# RA6M2 register map
Vendor: Renesas Electronics Corporation; Series: RA6; File version: 1.1
CPU: CM4 r0p1, little endian, MPU, FPU, VTOR, 4 interrupt priority bits
Registers are 8-bit, read-write, reset 0x0 unless marked. A register's access mark holds for its fields unless they carry their own. Offsets are from the block's base; [hi:lo] are bit positions; 'fields as' and 'values as' point back to an identical list.

## PMISC — Miscellaneous Port Control Register
Base 0x40040D00
0x00 PFENET — Ethernet Control Register
  [4] PHYMODE0 — Ethernet Mode Setting ch0
    0=RMII mode (ETHERC channel 0); 1=MII mode (ETHERC channel 0)
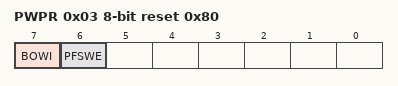
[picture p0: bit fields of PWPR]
0x03 PWPR reset 0x80 — Write-Protect Register
  [7] BOWI — PFSWE Bit Write Disable
    0=Writing to the PFSWE bit is enabled; 1=Writing to the PFSWE bit is disabled
  [6] PFSWE — PFS Register Write Enable
    0=Writing to the PFS register is disabled; 1=Writing to the PFS register is enabled

## CAC — Clock Frequency Accuracy Measurement Circuit
Base 0x40044600
0x00 CACR0 — CAC Control Register 0
  [0] CFME — Clock Frequency Measurement Enable.
    0=Disable; 1=Enable
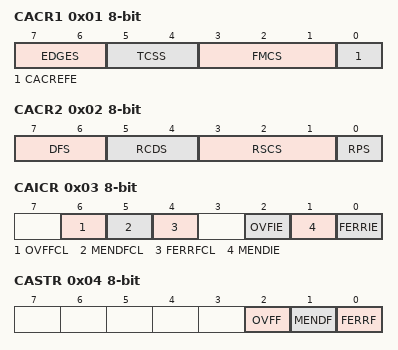
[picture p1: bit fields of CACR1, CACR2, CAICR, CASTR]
0x01 CACR1 — CAC Control Register 1
  [7:6] EDGES — Valid Edge Select
    0=Rising edge; 1=Falling edge; 2=Both rising and falling edges; 3=Setting prohibited
  [5:4] TCSS — Measurement Target Clock Frequency Division Ratio Select
    0=No division; 1=x 1/4 clock; 2=x 1/8 clock; 3=x 1/32 clock
  [3:1] FMCS — Measurement Target Clock Select
    0=Main clock; 1=Sub-clock; 2=HOCO clock; 3=MOCO clock; 4=LOCO clock; 5=Peripheral module clock(PCLKB); 6=IWDTCLK clock; 7=Setting prohibited
  [0] CACREFE — CACREF Pin Input Enable
    0=Disable; 1=Enable
0x02 CACR2 — CAC Control Register 2
  [7:6] DFS — Digital Filter Selection
    0=Digital filtering is disabled; 1=The sampling clock for the digital filter is the frequency measuring clock; 2=The sampling clock for the digital filter is the frequency measuring clock divided by 4; 3=The sampling clock for the digital filter is the frequency measuring clock divided by 16
  [5:4] RCDS — Measurement Reference Clock Frequency Division Ratio Select
    0=1/32 clock; 1=1/128 clock; 2=1/1024 clock; 3=1/8192 clock
  [3:1] RSCS — Measurement Reference Clock Select
    values as CACR1.FMCS
  [0] RPS — Reference Signal Select
    0=CACREF pin input; 1=Internal clock (internally generated signal)
0x03 CAICR — CAC Interrupt Control Register
  [6] OVFFCL wo — OVFF Clear
    0=No effect on operations; 1=Clears the OVFF flag
  [5] MENDFCL wo — MENDF Clear
    0=No effect on operations; 1=Clears the MENDF flag
  [4] FERRFCL wo — FERRF Clear
    0=No effect on operations; 1=Clears the FERRF flag
  [2] OVFIE — Overflow Interrupt Request Enable
    0=Disable; 1=Enable
  [1] MENDIE — Measurement End Interrupt Request Enable
    0=Disable; 1=Enable
  [0] FERRIE — Frequency Error Interrupt Request Enable
    0=Disable; 1=Enable
0x04 CASTR ro — CAC Status Register
  [2] OVFF — Counter Overflow Flag
    0=The counter has not overflowed; 1=The counter has overflowed
  [1] MENDF — Measurement End Flag
    0=Measurement is in progress; 1=Measurement has ended
  [0] FERRF — Frequency Error Flag
    0=The clock frequency is within the range corresponding to the settings; 1=The clock frequency has deviated beyond the range corresponding to the settings (frequency error)
0x06 CAULVR 16-bit — CAC Upper-Limit Value Setting Register
  [15:0] CAULVR — CAULVR is a 16-bit readable/writable register that stores the upper-limit value of the frequency.
0x08 CALLVR 16-bit — CAC Lower-Limit Value Setting Register
  [15:0] CALLVR — CALLVR is a 16-bit readable/writable register that stores the lower-limit value of the frequency.
0x0A CACNTBR 16-bit ro — CAC Counter Buffer Register
  [15:0] CACNTBR — CACNTBR is a 16-bit read-only register that retains the counter value at the time a valid reference signal edge is input

## DOC — Data Operation Circuit
Base 0x40054100
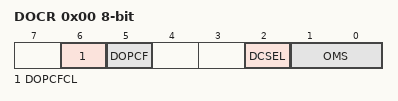
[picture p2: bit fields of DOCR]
0x00 DOCR — DOC Control Register
  [6] DOPCFCL — DOPCF Clear
    0=Maintains the DOPCF flag state; 1=Clears the DOPCF flag
  [5] DOPCF ro — Data Operation Circuit FlagIndicates the result of an operation.
  [2] DCSEL — Detection Condition Select
    0=DOPCF is set when data mismatch is detected; 1=DOPCF is set when data match is detected
  [1:0] OMS — Operating Mode Select
    0=Data comparison mode; 1=Data addition mode; 2=Data subtraction mode; 3=Setting prohibited
0x02 DODIR 16-bit — DOC Data Input Register
  [15:0] DODIR — 16-bit read-write register in which 16-bit data for use in the operations are stored.
0x04 DODSR 16-bit — DOC Data Setting Register
  [15:0] DODSR — This register stores 16-bit data for use as a reference in data comparison mode. This register also stores the results of operations in data addition and data subtraction modes.
